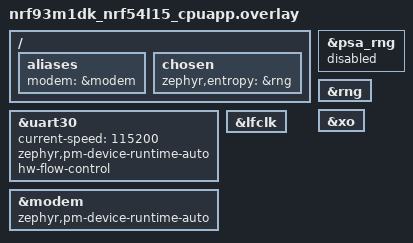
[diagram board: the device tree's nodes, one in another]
/*
 * Copyright (c) 2026 Nordic Semiconductor ASA
 *
 * SPDX-License-Identifier: LicenseRef-Nordic-5-Clause
 */

/ {
	aliases {
		modem = &modem;
	};

	chosen {
		zephyr,entropy = &rng;
	};
};

&uart30 {
	status = "okay";
	current-speed = <115200>;
	zephyr,pm-device-runtime-auto;
	hw-flow-control;
};

&modem {
	status = "okay";
	zephyr,pm-device-runtime-auto;
};

&psa_rng {
	status = "disabled";
};

&rng {
	status = "okay";
};

&xo {
	status = "okay";
};

&lfclk {
	status = "okay";
};
